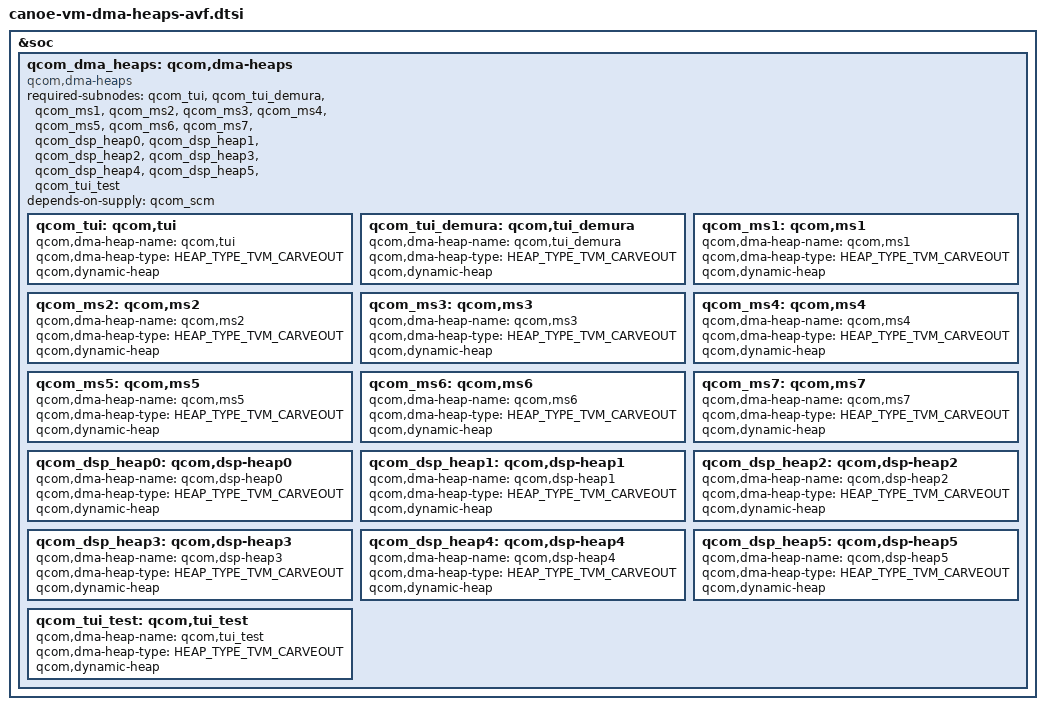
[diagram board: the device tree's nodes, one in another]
// SPDX-License-Identifier: BSD-3-Clause
/*
 * Copyright (c) 2025 Qualcomm Innovation Center, Inc. All rights reserved.
 */
#include <dt-bindings/arm/msm/qcom_dma_heap_dt_constants.h>

&soc {
	qcom_dma_heaps: qcom,dma-heaps {
		compatible = "qcom,dma-heaps";
		required-subnodes = <&qcom_tui
					&qcom_tui_demura
					&qcom_ms1
					&qcom_ms2
					&qcom_ms3
					&qcom_ms4
					&qcom_ms5
					&qcom_ms6
					&qcom_ms7
					&qcom_dsp_heap0
					&qcom_dsp_heap1
					&qcom_dsp_heap2
					&qcom_dsp_heap3
					&qcom_dsp_heap4
					&qcom_dsp_heap5
					&qcom_tui_test>;

		depends-on-supply = <&qcom_scm>;

		qcom_tui: qcom,tui {
			qcom,dma-heap-name = "qcom,tui";
			qcom,dma-heap-type = <HEAP_TYPE_TVM_CARVEOUT>;
			qcom,dynamic-heap;
		};

		qcom_tui_demura: qcom,tui_demura {
			qcom,dma-heap-name = "qcom,tui_demura";
			qcom,dma-heap-type = <HEAP_TYPE_TVM_CARVEOUT>;
			qcom,dynamic-heap;
		};

		qcom_ms1: qcom,ms1 {
			qcom,dma-heap-name = "qcom,ms1";
			qcom,dma-heap-type = <HEAP_TYPE_TVM_CARVEOUT>;
			qcom,dynamic-heap;
		};

		qcom_ms2: qcom,ms2 {
			qcom,dma-heap-name = "qcom,ms2";
			qcom,dma-heap-type = <HEAP_TYPE_TVM_CARVEOUT>;
			qcom,dynamic-heap;
		};

		qcom_ms3: qcom,ms3 {
			qcom,dma-heap-name = "qcom,ms3";
			qcom,dma-heap-type = <HEAP_TYPE_TVM_CARVEOUT>;
			qcom,dynamic-heap;
		};

		qcom_ms4: qcom,ms4 {
			qcom,dma-heap-name = "qcom,ms4";
			qcom,dma-heap-type = <HEAP_TYPE_TVM_CARVEOUT>;
			qcom,dynamic-heap;
		};

		qcom_ms5: qcom,ms5 {
			qcom,dma-heap-name = "qcom,ms5";
			qcom,dma-heap-type = <HEAP_TYPE_TVM_CARVEOUT>;
			qcom,dynamic-heap;
		};

		qcom_ms6: qcom,ms6 {
			qcom,dma-heap-name = "qcom,ms6";
			qcom,dma-heap-type = <HEAP_TYPE_TVM_CARVEOUT>;
			qcom,dynamic-heap;
		};

		qcom_ms7: qcom,ms7 {
			qcom,dma-heap-name = "qcom,ms7";
			qcom,dma-heap-type = <HEAP_TYPE_TVM_CARVEOUT>;
			qcom,dynamic-heap;
		};

		qcom_dsp_heap0: qcom,dsp-heap0 {
			qcom,dma-heap-name = "qcom,dsp-heap0";
			qcom,dma-heap-type = <HEAP_TYPE_TVM_CARVEOUT>;
			qcom,dynamic-heap;
		};

		qcom_dsp_heap1: qcom,dsp-heap1 {
			qcom,dma-heap-name = "qcom,dsp-heap1";
			qcom,dma-heap-type = <HEAP_TYPE_TVM_CARVEOUT>;
			qcom,dynamic-heap;
		};

		qcom_dsp_heap2: qcom,dsp-heap2 {
			qcom,dma-heap-name = "qcom,dsp-heap2";
			qcom,dma-heap-type = <HEAP_TYPE_TVM_CARVEOUT>;
			qcom,dynamic-heap;
		};

		qcom_dsp_heap3: qcom,dsp-heap3 {
			qcom,dma-heap-name = "qcom,dsp-heap3";
			qcom,dma-heap-type = <HEAP_TYPE_TVM_CARVEOUT>;
			qcom,dynamic-heap;
		};

		qcom_dsp_heap4: qcom,dsp-heap4 {
			qcom,dma-heap-name = "qcom,dsp-heap4";
			qcom,dma-heap-type = <HEAP_TYPE_TVM_CARVEOUT>;
			qcom,dynamic-heap;
		};

		qcom_dsp_heap5: qcom,dsp-heap5 {
			qcom,dma-heap-name = "qcom,dsp-heap5";
			qcom,dma-heap-type = <HEAP_TYPE_TVM_CARVEOUT>;
			qcom,dynamic-heap;
		};

		qcom_tui_test: qcom,tui_test {
			qcom,dma-heap-name = "qcom,tui_test";
			qcom,dma-heap-type = <HEAP_TYPE_TVM_CARVEOUT>;
			qcom,dynamic-heap;
		};
	};
};
